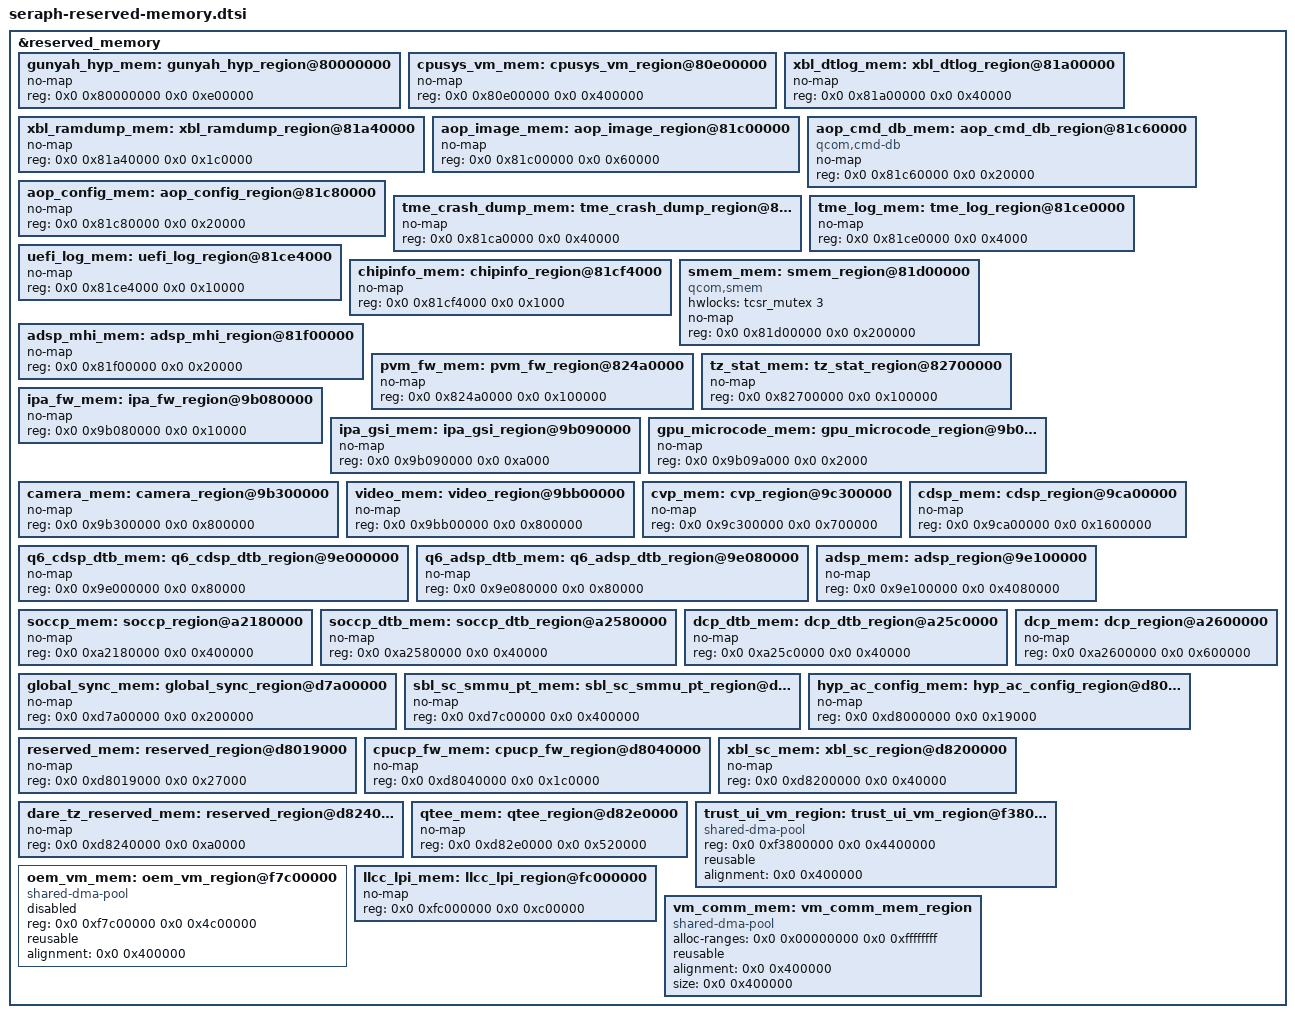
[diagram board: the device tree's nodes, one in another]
&reserved_memory {
	#address-cells = <2>;
	#size-cells = <2>;
	ranges;

	gunyah_hyp_mem: gunyah_hyp_region@80000000 {
		no-map;
		reg = <0x0 0x80000000 0x0 0xe00000>;
	};

	cpusys_vm_mem: cpusys_vm_region@80e00000 {
		no-map;
		reg = <0x0 0x80e00000 0x0 0x400000>;
	};

	/*
	 * hyp_tags_mem is dynamically removed from the RAM
	 * partition tables before boot occurs.
	 */

	xbl_dtlog_mem: xbl_dtlog_region@81a00000 {
		no-map;
		reg = <0x0 0x81a00000 0x0 0x40000>;
	};

	xbl_ramdump_mem: xbl_ramdump_region@81a40000 {
		no-map;
		reg = <0x0 0x81a40000 0x0 0x1c0000>;
	};

	aop_image_mem: aop_image_region@81c00000 {
		no-map;
		reg = <0x0 0x81c00000 0x0 0x60000>;
	};

	aop_cmd_db_mem: aop_cmd_db_region@81c60000 {
		compatible = "qcom,cmd-db";
		no-map;
		reg = <0x0 0x81c60000 0x0 0x20000>;
	};

	aop_config_mem: aop_config_region@81c80000 {
		no-map;
		reg = <0x0 0x81c80000 0x0 0x20000>;
	};

	tme_crash_dump_mem: tme_crash_dump_region@81ca0000 {
		no-map;
		reg = <0x0 0x81ca0000 0x0 0x40000>;
	};

	tme_log_mem: tme_log_region@81ce0000 {
		no-map;
		reg = <0x0 0x81ce0000 0x0 0x4000>;
	};

	uefi_log_mem: uefi_log_region@81ce4000 {
		no-map;
		reg = <0x0 0x81ce4000 0x0 0x10000>;
	};

	chipinfo_mem: chipinfo_region@81cf4000 {
		no-map;
		reg = <0x0 0x81cf4000 0x0 0x1000>;
	};

	/* secdata region can be reused by apps */

	smem_mem: smem_region@81d00000 {
		compatible = "qcom,smem";
		hwlocks = <&tcsr_mutex 3>;
		no-map;
		reg = <0x0 0x81d00000 0x0 0x200000>;
	};

	adsp_mhi_mem: adsp_mhi_region@81f00000 {
		no-map;
		reg = <0x0 0x81f00000 0x0 0x20000>;
	};

	/*
	 * hyp_mem_database_mem is dynamically removed from the RAM
	 * partition tables before boot occurs.
	 */

	pvm_fw_mem: pvm_fw_region@824a0000 {
		no-map;
		reg = <0x0 0x824a0000 0x0 0x100000>;
	};

	tz_stat_mem: tz_stat_region@82700000 {
		no-map;
		reg = <0x0 0x82700000 0x0 0x100000>;
	};

	ipa_fw_mem: ipa_fw_region@9b080000 {
		no-map;
		reg = <0x0 0x9b080000 0x0 0x10000>;
	};

	ipa_gsi_mem: ipa_gsi_region@9b090000 {
		no-map;
		reg = <0x0 0x9b090000 0x0 0xa000>;
	};

	gpu_microcode_mem: gpu_microcode_region@9b09a000 {
		no-map;
		reg = <0x0 0x9b09a000 0x0 0x2000>;
	};

	camera_mem: camera_region@9b300000 {
		no-map;
		reg = <0x0 0x9b300000 0x0 0x800000>;
	};

	video_mem: video_region@9bb00000 {
		no-map;
		reg = <0x0 0x9bb00000 0x0 0x800000>;
	};

	cvp_mem: cvp_region@9c300000 {
		no-map;
		reg = <0x0 0x9c300000 0x0 0x700000>;
	};

	cdsp_mem: cdsp_region@9ca00000 {
		no-map;
		reg = <0x0 0x9ca00000 0x0 0x1600000>;
	};

	q6_cdsp_dtb_mem: q6_cdsp_dtb_region@9e000000 {
		no-map;
		reg = <0x0 0x9e000000 0x0 0x80000>;
	};

	q6_adsp_dtb_mem: q6_adsp_dtb_region@9e080000 {
		no-map;
		reg = <0x0 0x9e080000 0x0 0x80000>;
	};

	adsp_mem: adsp_region@9e100000 {
		no-map;
		reg = <0x0 0x9e100000 0x0 0x4080000>;
	};

	soccp_mem: soccp_region@a2180000 {
		no-map;
		reg = <0x0 0xa2180000 0x0 0x400000>;
	};

	soccp_dtb_mem: soccp_dtb_region@a2580000 {
		no-map;
		reg = <0x0 0xa2580000 0x0 0x40000>;
	};

	dcp_dtb_mem: dcp_dtb_region@a25c0000 {
		no-map;
		reg = <0x0 0xa25c0000 0x0 0x40000>;
	};

	dcp_mem: dcp_region@a2600000 {
		no-map;
		reg = <0x0 0xa2600000 0x0 0x600000>;
	};

	/* UEFI region at 0xa7000000 is reclaimed by Linux */

	/* Linux kernel image is loaded at 0xa8000000 */

	global_sync_mem: global_sync_region@d7a00000 {
		no-map;
		reg = <0x0 0xd7a00000 0x0 0x200000>;
	};

	sbl_sc_smmu_pt_mem: sbl_sc_smmu_pt_region@d7c00000 {
		no-map;
		reg = <0x0 0xd7c00000 0x0 0x400000>;
	};

	hyp_ac_config_mem: hyp_ac_config_region@d8000000 {
		no-map;
		reg = <0x0 0xd8000000 0x0 0x19000>;
	};

	reserved_mem: reserved_region@d8019000 {
		no-map;
		reg = <0x0 0xd8019000 0x0 0x27000>;
	};

	cpucp_fw_mem: cpucp_fw_region@d8040000 {
		no-map;
		reg = <0x0 0xd8040000 0x0 0x1c0000>;
	};

	xbl_sc_mem: xbl_sc_region@d8200000 {
		no-map;
		reg = <0x0 0xd8200000 0x0 0x40000>;
	};

	dare_tz_reserved_mem: reserved_region@d8240000 {
		no-map;
		reg = <0x0 0xd8240000 0x0 0xa0000>;
	};

	qtee_mem: qtee_region@d82e0000 {
		no-map;
		reg = <0x0 0xd82e0000 0x0 0x520000>;
	};

	/*
	 * ta/tags_mem is dynamically removed from the RAM
	 * partition tables before boot occurs.
	 */

	trust_ui_vm_region: trust_ui_vm_region@f3800000 {
		compatible = "shared-dma-pool";
		reg = <0x0 0xf3800000 0x0 0x4400000>;
		reusable;
		alignment = <0x0 0x400000>;
	};

	oem_vm_mem: oem_vm_region@f7c00000 {
		compatible = "shared-dma-pool";
		reg = <0x0 0xf7c00000 0x0 0x4c00000>;
		reusable;
		alignment = <0x0 0x400000>;
		status = "disabled";
	};

	llcc_lpi_mem: llcc_lpi_region@fc000000 {
		no-map;
		reg = <0x0 0xfc000000 0x0 0xc00000>;
	};

	vm_comm_mem: vm_comm_mem_region {
		compatible = "shared-dma-pool";
		alloc-ranges = <0x0 0x00000000 0x0 0xffffffff>;
		reusable;
		alignment = <0x0 0x400000>;
		size = <0x0 0x400000>;
	};
};
